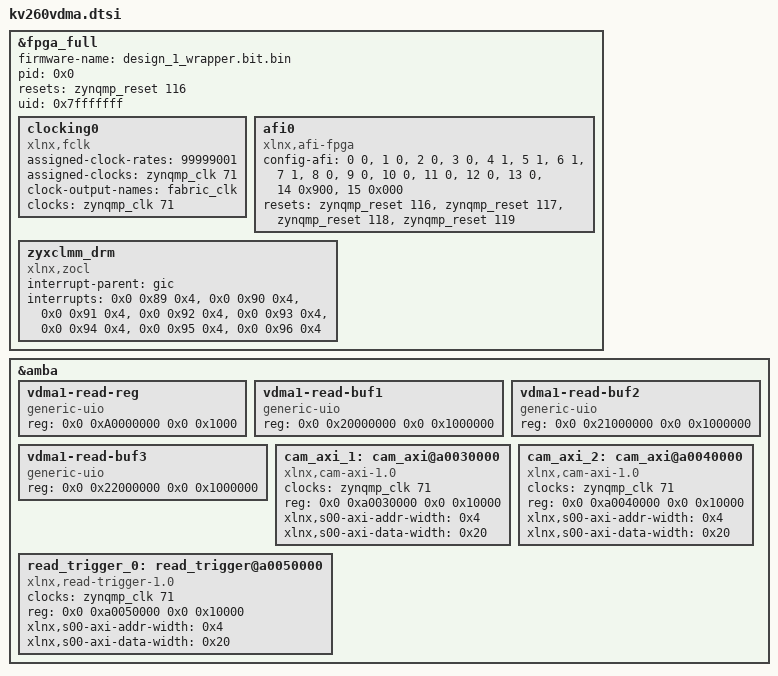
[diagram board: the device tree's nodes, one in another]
/*
 * CAUTION: This file is automatically generated by Xilinx.
 * Version: XSCT 2024.1
 * Today is: Tue Dec 30 11:33:09 2025
 */


/dts-v1/;
/plugin/;
&fpga_full {
	firmware-name = "design_1_wrapper.bit.bin";
	pid = <0x0>;
	resets = <&zynqmp_reset 116>;
	uid = <0x7fffffff>;
	clocking0: clocking0 {
		#clock-cells = <0>;
		assigned-clock-rates = <99999001>;
		assigned-clocks = <&zynqmp_clk 71>;
		clock-output-names = "fabric_clk";
		clocks = <&zynqmp_clk 71>;
		compatible = "xlnx,fclk";
	};
	afi0: afi0 {
		compatible = "xlnx,afi-fpga";
		config-afi = < 0 0>, <1 0>, <2 0>, <3 0>, <4 1>, <5 1>, <6 1>, <7 1>, <8 0>, <9 0>, <10 0>, <11 0>, <12 0>, <13 0>, <14 0x900>, <15 0x000>;
		resets = <&zynqmp_reset 116>, <&zynqmp_reset 117>, <&zynqmp_reset 118>, <&zynqmp_reset 119>;
	};
	zyxclmm_drm {
		compatible = "xlnx,zocl";
		interrupt-parent = <&gic>;
		interrupts = <0x0 0x89 0x4>, <0x0 0x90 0x4>, <0x0 0x91 0x4>, <0x0 0x92 0x4>, <0x0 0x93 0x4>, <0x0 0x94 0x4>, <0x0 0x95 0x4>, <0x0 0x96 0x4>;
	};
};
&amba {
	#address-cells = <2>;
	#size-cells = <2>;
    
    vdma1-read-reg {
		compatible = "generic-uio";
        reg = <0x0 0xA0000000 0x0 0x1000>;
	};
	
	vdma1-read-buf1 {
		compatible = "generic-uio";
        reg = <0x0 0x20000000 0x0 0x1000000>;
	};
	
	vdma1-read-buf2 {
		compatible = "generic-uio";
        reg = <0x0 0x21000000 0x0 0x1000000>;
	};
	
	vdma1-read-buf3 {
		compatible = "generic-uio";
        reg = <0x0 0x22000000 0x0 0x1000000>;
	};
    
	cam_axi_1: cam_axi@a0030000 {
		/* This is a place holder node for a custom IP, user may need to update the entries */
		clock-names = "s00_axi_aclk";
		clocks = <&zynqmp_clk 71>;
		compatible = "xlnx,cam-axi-1.0";
		reg = <0x0 0xa0030000 0x0 0x10000>;
		xlnx,s00-axi-addr-width = <0x4>;
		xlnx,s00-axi-data-width = <0x20>;
	};
	cam_axi_2: cam_axi@a0040000 {
		/* This is a place holder node for a custom IP, user may need to update the entries */
		clock-names = "s00_axi_aclk";
		clocks = <&zynqmp_clk 71>;
		compatible = "xlnx,cam-axi-1.0";
		reg = <0x0 0xa0040000 0x0 0x10000>;
		xlnx,s00-axi-addr-width = <0x4>;
		xlnx,s00-axi-data-width = <0x20>;
	};
	read_trigger_0: read_trigger@a0050000 {
		/* This is a place holder node for a custom IP, user may need to update the entries */
		clock-names = "s00_axi_aclk";
		clocks = <&zynqmp_clk 71>;
		compatible = "xlnx,read-trigger-1.0";
		reg = <0x0 0xa0050000 0x0 0x10000>;
		xlnx,s00-axi-addr-width = <0x4>;
		xlnx,s00-axi-data-width = <0x20>;
	};
};
